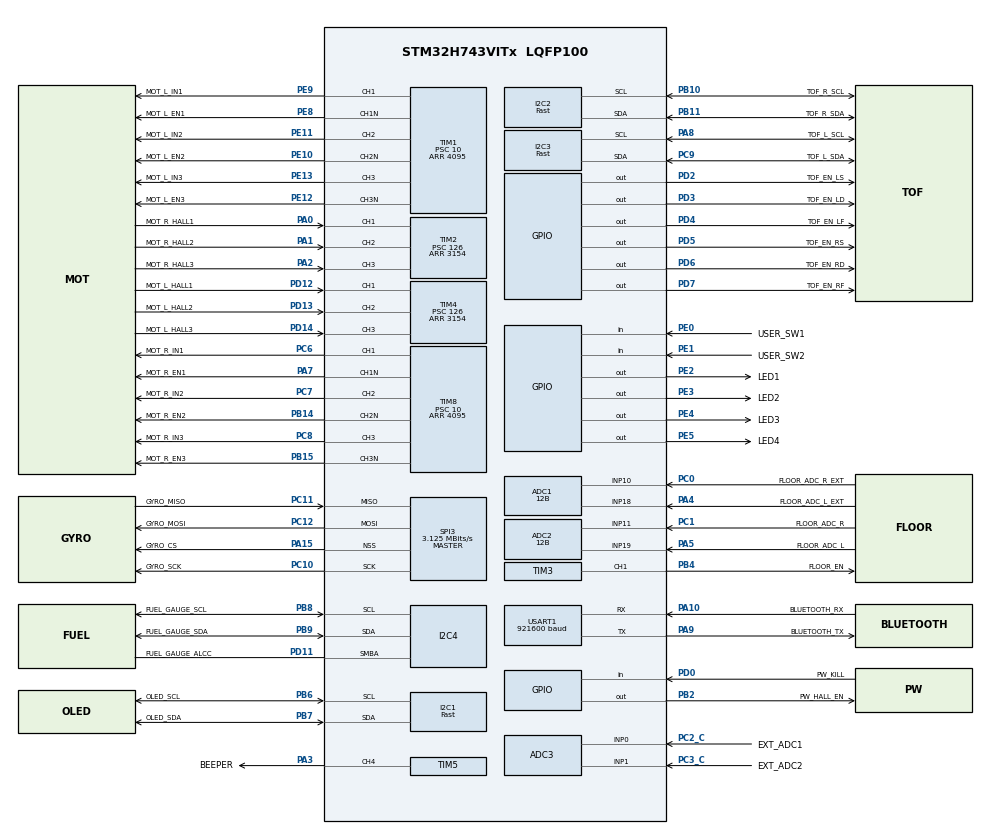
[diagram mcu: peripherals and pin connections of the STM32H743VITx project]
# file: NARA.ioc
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ADC1.BoostMode=ENABLE
ADC1.ClockPrescaler=ADC_CLOCK_ASYNC_DIV6
ADC1.ContinuousConvMode=DISABLE
ADC1.ConversionDataManagement=ADC_CONVERSIONDATA_DR
ADC1.DMAContinuousRequests=DISABLE
ADC1.DiscontinuousConvMode=DISABLE
ADC1.EOCSelection=ADC_EOC_SINGLE_CONV
ADC1.EnableAnalogWatchDog1=false
ADC1.EnableAnalogWatchDog2=false
ADC1.EnableAnalogWatchDog3=false
ADC1.EnableInjectedConversion=ENABLE
ADC1.EnableInjectedOversampling=DISABLE
ADC1.EnableRegularConversion=DISABLE
ADC1.ExternalTrigInjecConv=ADC_INJECTED_SOFTWARE_START
ADC1.ExternalTrigInjecConvEdge=ADC_EXTERNALTRIGINJECCONV_EDGE_NONE
ADC1.InjNumberOfConversion=2
ADC1.InjectedChannel-32\#ChannelInjectedConversion=ADC_CHANNEL_18
ADC1.InjectedChannel-33\#ChannelInjectedConversion=ADC_CHANNEL_10
ADC1.InjectedConvMode=None
ADC1.InjectedLeftBitShift=ADC_LEFTBITSHIFT_NONE
ADC1.InjectedOffsetNumber-32\#ChannelInjectedConversion=ADC_OFFSET_NONE
ADC1.InjectedOffsetNumber-33\#ChannelInjectedConversion=ADC_OFFSET_NONE
ADC1.InjectedQueue=DISABLE
ADC1.InjectedRank-32\#ChannelInjectedConversion=1
ADC1.InjectedRank-33\#ChannelInjectedConversion=2
ADC1.InjectedSamplingTime-32\#ChannelInjectedConversion=ADC_SAMPLETIME_2CYCLES_5
ADC1.InjectedSamplingTime-33\#ChannelInjectedConversion=ADC_SAMPLETIME_2CYCLES_5
ADC1.LowPowerAutoWait=DISABLE
ADC1.Overrun=ADC_OVR_DATA_PRESERVED
ADC1.Resolution=ADC_RESOLUTION_12B
ADC1.ScanConvMode=ADC_SCAN_ENABLE
ADC1.master=1
ADC2.EnableInjectedConversion=ENABLE
ADC2.EnableRegularConversion=DISABLE
ADC2.InjNumberOfConversion=2
ADC2.InjectedChannel-27\#ChannelInjectedConversion=ADC_CHANNEL_19
ADC2.InjectedChannel-28\#ChannelInjectedConversion=ADC_CHANNEL_11
ADC2.InjectedOffsetNumber-27\#ChannelInjectedConversion=ADC_OFFSET_NONE
ADC2.InjectedOffsetNumber-28\#ChannelInjectedConversion=ADC_OFFSET_NONE
ADC2.InjectedRank-27\#ChannelInjectedConversion=1
ADC2.InjectedRank-28\#ChannelInjectedConversion=2
ADC2.InjectedSamplingTime-27\#ChannelInjectedConversion=ADC_SAMPLETIME_2CYCLES_5
ADC2.InjectedSamplingTime-28\#ChannelInjectedConversion=ADC_SAMPLETIME_2CYCLES_5
ADC2.Resolution=ADC_RESOLUTION_12B
ADC3.Channel-0\#ChannelRegularConversion=ADC_CHANNEL_0
ADC3.NbrOfConversionFlag=1
ADC3.OffsetNumber-0\#ChannelRegularConversion=ADC_OFFSET_NONE
ADC3.Rank-0\#ChannelRegularConversion=1
ADC3.SamplingTime-0\#ChannelRegularConversion=ADC_SAMPLETIME_1CYCLE_5
CORTEX_M7.CPU_DCache=Enabled
CORTEX_M7.CPU_ICache=Enabled
Dma.Request0=USART1_TX
Dma.USART1_TX.0.Direction=DMA_MEMORY_TO_PERIPH
Dma.USART1_TX.0.EventEnable=DISABLE
Dma.USART1_TX.0.FIFOMode=DMA_FIFOMODE_DISABLE
Dma.USART1_TX.0.Instance=DMA2_Stream7
Dma.USART1_TX.0.MemDataAlignment=DMA_MDATAALIGN_BYTE
Dma.USART1_TX.0.MemInc=DMA_MINC_ENABLE
Dma.USART1_TX.0.Mode=DMA_NORMAL
Dma.USART1_TX.0.PeriphDataAlignment=DMA_PDATAALIGN_BYTE
Dma.USART1_TX.0.PeriphInc=DMA_PINC_DISABLE
Dma.USART1_TX.0.Polarity=HAL_DMAMUX_REQ_GEN_RISING
Dma.USART1_TX.0.Priority=DMA_PRIORITY_LOW
Dma.USART1_TX.0.RequestNumber=1
Dma.USART1_TX.0.SyncEnable=DISABLE
Dma.USART1_TX.0.SyncPolarity=HAL_DMAMUX_SYNC_NO_EVENT
Dma.USART1_TX.0.SyncRequestNumber=1
I2C1.Analog_Filter=I2C_ANALOGFILTER_DISABLE
I2C1.I2C_Speed_Mode=I2C_Fast
I2C1.Timing=0x009039BB
I2C2.Analog_Filter=I2C_ANALOGFILTER_DISABLE
I2C2.I2C_Speed_Mode=I2C_Fast
I2C2.Timing=0x009039BB
I2C3.Analog_Filter=I2C_ANALOGFILTER_DISABLE
I2C3.I2C_Speed_Mode=I2C_Fast
I2C3.Timing=0x009039BB
I2C4.SMBusAnalogFilter=SMBUS_ANALOGFILTER_DISABLE
I2C4.Timeout=0x000084C4
I2C4.Timing=0x10C0F1FF
Mcu.Family=STM32H7
Mcu.Name=STM32H743VITx
Mcu.Package=LQFP100
NVIC.ADC_IRQn=true\:0\:0\:false\:false\:true\:true
NVIC.DMA2_Stream7_IRQn=true\:0\:0\:false\:false\:true\:false
NVIC.PriorityGroup=NVIC_PRIORITYGROUP_1
NVIC.TIM1_BRK_IRQn=true\:1\:0\:true\:false\:true\:true
NVIC.TIM1_TRG_COM_IRQn=true\:0\:2\:false\:false\:true\:true
NVIC.TIM2_IRQn=true\:0\:1\:false\:false\:true\:true
NVIC.TIM4_IRQn=true\:0\:1\:false\:false\:true\:true
NVIC.TIM6_DAC_IRQn=true\:1\:0\:true\:false\:true\:true
NVIC.TIM7_IRQn=true\:0\:3\:false\:false\:true\:true
NVIC.TIM8_BRK_TIM12_IRQn=true\:1\:0\:true\:false\:true\:true
NVIC.TIM8_TRG_COM_TIM14_IRQn=true\:0\:2\:false\:false\:true\:true
NVIC.USART1_IRQn=true\:0\:1\:false\:false\:true\:true
PA0-WKUP.GPIO_Label=MOT_R_HALL1
PA0-WKUP.GPIO_PuPd=GPIO_PULLUP
PA0-WKUP.GPIO_Speed=GPIO_SPEED_FREQ_VERY_HIGH
PA0-WKUP.Signal=S_TIM2_CH1
PA1.GPIO_Label=MOT_R_HALL2
PA1.GPIO_PuPd=GPIO_PULLUP
PA1.GPIO_Speed=GPIO_SPEED_FREQ_VERY_HIGH
PA1.Signal=S_TIM2_CH2
PA10.GPIO_Label=BLUETOOTH_RX
PA10.GPIO_Speed=GPIO_SPEED_FREQ_VERY_HIGH
PA10.Mode=Asynchronous
PA10.Signal=USART1_RX
PA13.Mode=Serial_Wire
PA13.Signal=SYS_JTMS-SWDIO
PA14.Mode=Serial_Wire
PA14.Signal=SYS_JTCK-SWCLK
PA15.GPIO_Label=GYRO_CS
PA15.GPIO_Speed=GPIO_SPEED_FREQ_VERY_HIGH
PA15.Mode=NSS_Signal_Hard_Output
PA15.Signal=SPI3_NSS
PA2.GPIO_Label=MOT_R_HALL3
PA2.GPIO_PuPd=GPIO_PULLUP
PA2.GPIO_Speed=GPIO_SPEED_FREQ_VERY_HIGH
PA2.Signal=S_TIM2_CH3
PA3.GPIO_Label=BEEPER
PA3.GPIO_Speed=GPIO_SPEED_FREQ_VERY_HIGH
PA3.Signal=S_TIM5_CH4
PA4.GPIO_Label=FLOOR_ADC_L_EXT
PA4.Signal=ADCx_INP18
PA5.GPIO_Label=FLOOR_ADC_L
PA5.Signal=ADCx_INP19
PA7.GPIO_Label=MOT_R_EN1
PA7.GPIO_Speed=GPIO_SPEED_FREQ_VERY_HIGH
PA7.Mode=Output Compare1 CH1 CH1N
PA7.Signal=TIM8_CH1N
PA8.GPIO_Label=TOF_L_SCL
PA8.GPIO_PuPd=GPIO_PULLUP
PA8.GPIO_Speed=GPIO_SPEED_FREQ_VERY_HIGH
PA8.Mode=I2C
PA8.Signal=I2C3_SCL
PA9.GPIO_Label=BLUETOOTH_TX
PA9.GPIO_Speed=GPIO_SPEED_FREQ_VERY_HIGH
PA9.Mode=Asynchronous
PA9.Signal=USART1_TX
PB10.GPIO_Label=TOF_R_SCL
PB10.GPIO_PuPd=GPIO_PULLUP
PB10.GPIO_Speed=GPIO_SPEED_FREQ_VERY_HIGH
PB10.Mode=I2C
PB10.Signal=I2C2_SCL
PB11.GPIO_Label=TOF_R_SDA
PB11.GPIO_PuPd=GPIO_PULLUP
PB11.GPIO_Speed=GPIO_SPEED_FREQ_VERY_HIGH
PB11.Mode=I2C
PB11.Signal=I2C2_SDA
PB14.GPIO_Label=MOT_R_EN2
PB14.GPIO_Speed=GPIO_SPEED_FREQ_VERY_HIGH
PB14.Mode=Output Compare2 CH2 CH2N
PB14.Signal=TIM8_CH2N
PB15.GPIO_Label=MOT_R_EN3
PB15.GPIO_Speed=GPIO_SPEED_FREQ_VERY_HIGH
PB15.Mode=Output Compare3 CH3 CH3N
PB15.Signal=TIM8_CH3N
PB2.GPIO_Label=PW_HALL_EN
PB2.Signal=GPIO_Output
PB4.GPIO_Label=FLOOR_EN
PB4.Signal=S_TIM3_CH1
PB6.GPIO_Label=OLED_SCL
PB6.GPIO_Speed=GPIO_SPEED_FREQ_VERY_HIGH
PB6.Mode=I2C
PB6.Signal=I2C1_SCL
PB7.GPIO_Label=OLED_SDA
PB7.GPIO_Speed=GPIO_SPEED_FREQ_VERY_HIGH
PB7.Mode=I2C
PB7.Signal=I2C1_SDA
PB8.GPIO_Label=FUEL_GAUGE_SCL
PB8.GPIO_Speed=GPIO_SPEED_FREQ_VERY_HIGH
PB8.Mode=SMBus-Alert-mode
PB8.Signal=I2C4_SCL
PB9.GPIO_Label=FUEL_GAUGE_SDA
PB9.GPIO_Speed=GPIO_SPEED_FREQ_VERY_HIGH
PB9.Mode=SMBus-Alert-mode
PB9.Signal=I2C4_SDA
PC0.GPIO_Label=FLOOR_ADC_R_EXT
PC0.Signal=ADCx_INP10
PC1.GPIO_Label=FLOOR_ADC_R
PC1.Signal=ADCx_INP11
PC10.GPIO_Label=GYRO_SCK
PC10.GPIO_Speed=GPIO_SPEED_FREQ_VERY_HIGH
PC10.Mode=Full_Duplex_Master
PC10.Signal=SPI3_SCK
PC11.GPIO_Label=GYRO_MISO
PC11.GPIO_Speed=GPIO_SPEED_FREQ_VERY_HIGH
PC11.Mode=Full_Duplex_Master
PC11.Signal=SPI3_MISO
PC12.GPIO_Label=GYRO_MOSI
PC12.GPIO_Speed=GPIO_SPEED_FREQ_VERY_HIGH
PC12.Mode=Full_Duplex_Master
PC12.Signal=SPI3_MOSI
PC13.GPIO_Label=WKUP
PC13.Mode=SYS_WakeUp2
PC13.Signal=SYS_WKUP2
PC2_C.GPIO_Label=EXT_ADC1
PC2_C.Mode=IN0-Single-Ended
PC2_C.Signal=ADC3_INP0
PC3_C.GPIO_Label=EXT_ADC2
PC3_C.Mode=IN1-Single-Ended
PC3_C.Signal=ADC3_INP1
PC6.GPIO_Label=MOT_R_IN1
PC6.GPIO_Speed=GPIO_SPEED_FREQ_VERY_HIGH
PC6.Signal=S_TIM8_CH1
PC7.GPIO_Label=MOT_R_IN2
PC7.GPIO_Speed=GPIO_SPEED_FREQ_VERY_HIGH
PC7.Signal=S_TIM8_CH2
PC8.GPIO_Label=MOT_R_IN3
PC8.GPIO_Speed=GPIO_SPEED_FREQ_VERY_HIGH
PC8.Signal=S_TIM8_CH3
PC9.GPIO_Label=TOF_L_SDA
PC9.GPIO_PuPd=GPIO_PULLUP
PC9.GPIO_Speed=GPIO_SPEED_FREQ_VERY_HIGH
PC9.Mode=I2C
PC9.Signal=I2C3_SDA
PD0.GPIO_Label=PW_KILL
PD0.Signal=GPIO_Input
PD11.GPIO_Label=FUEL_GAUGE_ALCC
PD11.GPIO_Speed=GPIO_SPEED_FREQ_VERY_HIGH
PD11.Mode=SMBus-Alert-mode
PD11.Signal=I2C4_SMBA
PD12.GPIO_Label=MOT_L_HALL1
PD12.GPIO_PuPd=GPIO_PULLUP
PD12.GPIO_Speed=GPIO_SPEED_FREQ_VERY_HIGH
PD12.Signal=S_TIM4_CH1
PD13.GPIO_Label=MOT_L_HALL2
PD13.GPIO_PuPd=GPIO_PULLUP
PD13.GPIO_Speed=GPIO_SPEED_FREQ_VERY_HIGH
PD13.Signal=S_TIM4_CH2
PD14.GPIO_Label=MOT_L_HALL3
PD14.GPIO_PuPd=GPIO_PULLUP
PD14.GPIO_Speed=GPIO_SPEED_FREQ_VERY_HIGH
PD14.Signal=S_TIM4_CH3
PD2.GPIO_Label=TOF_EN_LS
PD2.GPIO_Speed=GPIO_SPEED_FREQ_MEDIUM
PD2.PinState=GPIO_PIN_RESET
PD2.Signal=GPIO_Output
PD3.GPIO_Label=TOF_EN_LD
PD3.GPIO_Speed=GPIO_SPEED_FREQ_MEDIUM
PD3.PinState=GPIO_PIN_RESET
PD3.Signal=GPIO_Output
PD4.GPIO_Label=TOF_EN_LF
PD4.GPIO_Speed=GPIO_SPEED_FREQ_MEDIUM
PD4.PinState=GPIO_PIN_RESET
PD4.Signal=GPIO_Output
PD5.GPIO_Label=TOF_EN_RS
PD5.GPIO_Speed=GPIO_SPEED_FREQ_MEDIUM
PD5.PinState=GPIO_PIN_RESET
PD5.Signal=GPIO_Output
PD6.GPIO_Label=TOF_EN_RD
PD6.GPIO_Speed=GPIO_SPEED_FREQ_MEDIUM
PD6.PinState=GPIO_PIN_RESET
PD6.Signal=GPIO_Output
PD7.GPIO_Label=TOF_EN_RF
PD7.GPIO_Speed=GPIO_SPEED_FREQ_MEDIUM
PD7.PinState=GPIO_PIN_RESET
PD7.Signal=GPIO_Output
PE0.GPIO_Label=USER_SW1
PE0.Signal=GPIO_Input
PE1.GPIO_Label=USER_SW2
PE1.Signal=GPIO_Input
PE10.GPIO_Label=MOT_L_EN2
PE10.GPIO_Speed=GPIO_SPEED_FREQ_VERY_HIGH
PE10.Mode=Output Compare2 CH2 CH2N
PE10.Signal=TIM1_CH2N
PE11.GPIO_Label=MOT_L_IN2
PE11.GPIO_Speed=GPIO_SPEED_FREQ_VERY_HIGH
PE11.Signal=S_TIM1_CH2
PE12.GPIO_Label=MOT_L_EN3
PE12.GPIO_Speed=GPIO_SPEED_FREQ_VERY_HIGH
PE12.Mode=Output Compare3 CH3 CH3N
PE12.Signal=TIM1_CH3N
PE13.GPIO_Label=MOT_L_IN3
PE13.GPIO_Speed=GPIO_SPEED_FREQ_VERY_HIGH
PE13.Signal=S_TIM1_CH3
PE2.GPIO_Label=LED1
PE2.GPIO_Speed=GPIO_SPEED_FREQ_VERY_HIGH
PE2.Signal=GPIO_Output
PE3.GPIO_Label=LED2
PE3.GPIO_Speed=GPIO_SPEED_FREQ_VERY_HIGH
PE3.Signal=GPIO_Output
PE4.GPIO_Label=LED3
PE4.GPIO_Speed=GPIO_SPEED_FREQ_VERY_HIGH
PE4.Signal=GPIO_Output
PE5.GPIO_Label=LED4
PE5.GPIO_Speed=GPIO_SPEED_FREQ_VERY_HIGH
PE5.Signal=GPIO_Output
PE8.GPIO_Label=MOT_L_EN1
PE8.GPIO_Speed=GPIO_SPEED_FREQ_VERY_HIGH
PE8.Mode=Output Compare1 CH1 CH1N
PE8.Signal=TIM1_CH1N
PE9.GPIO_Label=MOT_L_IN1
PE9.GPIO_Speed=GPIO_SPEED_FREQ_VERY_HIGH
PE9.Signal=S_TIM1_CH1
ProjectManager.HeapSize=0x200
ProjectManager.StackSize=0x400
ProjectManager.TargetToolchain=SW4STM32
RCC.ADCFreq_Value=160000000
RCC.APB1Freq_Value=100000000
RCC.APB2Freq_Value=100000000
RCC.APB3Freq_Value=100000000
RCC.APB4Freq_Value=100000000
RCC.CortexFreq_Value=400000000
RCC.D1PPRE=RCC_APB3_DIV2
RCC.D2PPRE1=RCC_APB1_DIV2
RCC.D2PPRE2=RCC_APB2_DIV2
RCC.D3PPRE=RCC_APB4_DIV2
RCC.DIVM1=4
RCC.DIVM2=4
RCC.DIVN1=50
RCC.DIVN2=10
RCC.DIVP2=1
RCC.FLatency=FLASH_LATENCY_4
RCC.HCLKFreq_Value=200000000
RCC.HPRE=RCC_HCLK_DIV2
RCC.SYSCLKFreq_VALUE=400000000
RCC.SYSCLKSource=RCC_SYSCLKSOURCE_PLLCLK
RCC.USBFreq_Value=400000000
SH.ADCx_INP10.0=ADC1_INP10,IN10-Single-Ended
SH.ADCx_INP11.0=ADC2_INP11,IN11-Single-Ended
SH.ADCx_INP18.0=ADC1_INP18,IN18-Single-Ended
SH.ADCx_INP19.0=ADC2_INP19,IN19-Single-Ended
SH.S_TIM1_CH1.0=TIM1_CH1,Output Compare1 CH1 CH1N
SH.S_TIM1_CH2.0=TIM1_CH2,Output Compare2 CH2 CH2N
SH.S_TIM1_CH3.0=TIM1_CH3,Output Compare3 CH3 CH3N
SH.S_TIM2_CH1.0=TIM2_CH1,Xored_Inputs_Hall_Sensor_Interface
SH.S_TIM2_CH2.0=TIM2_CH2,Xored_Inputs_Hall_Sensor_Interface
SH.S_TIM2_CH3.0=TIM2_CH3,Xored_Inputs_Hall_Sensor_Interface
SH.S_TIM3_CH1.0=TIM3_CH1,PWM Generation1 CH1
SH.S_TIM4_CH1.0=TIM4_CH1,Xored_Inputs_Hall_Sensor_Interface
SH.S_TIM4_CH2.0=TIM4_CH2,Xored_Inputs_Hall_Sensor_Interface
SH.S_TIM4_CH3.0=TIM4_CH3,Xored_Inputs_Hall_Sensor_Interface
SH.S_TIM5_CH4.0=TIM5_CH4,PWM Generation4 CH4
SH.S_TIM8_CH1.0=TIM8_CH1,Output Compare1 CH1 CH1N
SH.S_TIM8_CH2.0=TIM8_CH2,Output Compare2 CH2 CH2N
SH.S_TIM8_CH3.0=TIM8_CH3,Output Compare3 CH3 CH3N
SPI3.BaudRatePrescaler=SPI_BAUDRATEPRESCALER_128
SPI3.CalculateBaudRate=3.125 MBits/s
SPI3.Direction=SPI_DIRECTION_2LINES
SPI3.Mode=SPI_MODE_MASTER
SPI3.VirtualNSS=VM_NSSHARD
SPI3.VirtualType=VM_MASTER
TIM1.AutomaticOutput=TIM_AUTOMATICOUTPUT_ENABLE
TIM1.Break2State=TIM_BREAK2_DISABLE
TIM1.Channel-Output\ Compare1\ CH1\ CH1N=TIM_CHANNEL_1
TIM1.Channel-Output\ Compare2\ CH2\ CH2N=TIM_CHANNEL_2
TIM1.Channel-Output\ Compare3\ CH3\ CH3N=TIM_CHANNEL_3
TIM1.DeadTime=18
TIM1.OCIdleState_1=TIM_OCIDLESTATE_SET
TIM1.OCIdleState_2=TIM_OCIDLESTATE_SET
TIM1.OCIdleState_3=TIM_OCIDLESTATE_SET
TIM1.OCNIdleState_1=TIM_OCNIDLESTATE_SET
TIM1.OCNIdleState_2=TIM_OCNIDLESTATE_SET
TIM1.OCNIdleState_3=TIM_OCNIDLESTATE_SET
TIM1.OffStateIDLEMode=TIM_OSSI_ENABLE
TIM1.OffStateRunMode=TIM_OSSR_ENABLE
TIM1.Period=4095
TIM1.Prescaler=10
TIM1.Pulse-Output\ Compare1\ CH1\ CH1N=2047
TIM1.Pulse-Output\ Compare2\ CH2\ CH2N=1023
TIM1.Pulse-Output\ Compare3\ CH3\ CH3N=511
TIM2.Commutation_Delay=1
TIM2.IC1Filter=0xF
TIM2.Period=3154
TIM2.Prescaler=126
TIM3.Channel-PWM\ Generation1\ CH1=TIM_CHANNEL_1
TIM3.Period=1000
TIM3.Prescaler=1000
TIM4.Commutation_Delay=1
TIM4.IC1Filter=0xF
TIM4.Period=3154
TIM4.Prescaler=126
TIM5.Channel-PWM\ Generation4\ CH4=TIM_CHANNEL_4
TIM5.OCPolarity_4=TIM_OCPOLARITY_LOW
TIM5.Period=100
TIM5.Prescaler=10000
TIM5.Pulse-PWM\ Generation4\ CH4=50
TIM6.Period=10
TIM6.Prescaler=60000
TIM7.Period=10
TIM7.Prescaler=60000
TIM8.AutomaticOutput=TIM_AUTOMATICOUTPUT_ENABLE
TIM8.Channel-Output\ Compare1\ CH1\ CH1N=TIM_CHANNEL_1
TIM8.Channel-Output\ Compare2\ CH2\ CH2N=TIM_CHANNEL_2
TIM8.Channel-Output\ Compare3\ CH3\ CH3N=TIM_CHANNEL_3
TIM8.DeadTime=18
TIM8.OCIdleState_1=TIM_OCIDLESTATE_SET
TIM8.OCIdleState_2=TIM_OCIDLESTATE_SET
TIM8.OCIdleState_3=TIM_OCIDLESTATE_SET
TIM8.OCNIdleState_1=TIM_OCNIDLESTATE_SET
TIM8.OCNIdleState_2=TIM_OCNIDLESTATE_SET
TIM8.OCNIdleState_3=TIM_OCNIDLESTATE_SET
TIM8.OffStateIDLEMode=TIM_OSSI_ENABLE
TIM8.OffStateRunMode=TIM_OSSR_ENABLE
TIM8.Period=4095
TIM8.Prescaler=10
TIM8.Pulse-Output\ Compare1\ CH1\ CH1N=2047
TIM8.Pulse-Output\ Compare2\ CH2\ CH2N=1023
TIM8.Pulse-Output\ Compare3\ CH3\ CH3N=511
USART1.BaudRate=921600
USART1.VirtualMode-Asynchronous=VM_ASYNC
USART1.WordLength=WORDLENGTH_8B
VP_TIM1_VS_ClockSourceITR.Mode=TriggerSource_ITR3
VP_TIM1_VS_ControllerModeTrigger.Mode=Trigger Mode
VP_TIM2_VS_ClockSourceINT.Mode=Internal
VP_TIM3_VS_ClockSourceINT.Mode=Internal
VP_TIM4_VS_ClockSourceINT.Mode=Internal
VP_TIM6_VS_ClockSourceINT.Mode=Enable_Timer
VP_TIM7_VS_ClockSourceINT.Mode=Enable_Timer
VP_TIM8_VS_ClockSourceITR.Mode=TriggerSource_ITR1
VP_TIM8_VS_ControllerModeTrigger.Mode=Trigger Mode
board=NARA

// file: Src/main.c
/**
  ******************************************************************************
  * @file           : main.c
  * @brief          : Main program body
  ******************************************************************************
  ** This notice applies to any and all portions of this file
  * that are not between comment pairs USER CODE BEGIN and
  * USER CODE END. Other portions of this file, whether
  * inserted by the user or by software development tools
  * are owned by their respective copyright owners.
  *
  * COPYRIGHT(c) 2018 STMicroelectronics
  *
  * Redistribution and use in source and binary forms, with or without modification,
  * are permitted provided that the following conditions are met:
  *   1. Redistributions of source code must retain the above copyright notice,
  *      this list of conditions and the following disclaimer.
  *   2. Redistributions in binary form must reproduce the above copyright notice,
  *      this list of conditions and the following disclaimer in the documentation
  *      and/or other materials provided with the distribution.
  *   3. Neither the name of STMicroelectronics nor the names of its contributors
  *      may be used to endorse or promote products derived from this software
  *      without specific prior written permission.
  *
  * THIS SOFTWARE IS PROVIDED BY THE COPYRIGHT HOLDERS AND CONTRIBUTORS "AS IS"
  * AND ANY EXPRESS OR IMPLIED WARRANTIES, INCLUDING, BUT NOT LIMITED TO, THE
  * IMPLIED WARRANTIES OF MERCHANTABILITY AND FITNESS FOR A PARTICULAR PURPOSE ARE
  * DISCLAIMED. IN NO EVENT SHALL THE COPYRIGHT HOLDER OR CONTRIBUTORS BE LIABLE
  * FOR ANY DIRECT, INDIRECT, INCIDENTAL, SPECIAL, EXEMPLARY, OR CONSEQUENTIAL
  * DAMAGES (INCLUDING, BUT NOT LIMITED TO, PROCUREMENT OF SUBSTITUTE GOODS OR
  * SERVICES; LOSS OF USE, DATA, OR PROFITS; OR BUSINESS INTERRUPTION) HOWEVER
  * CAUSED AND ON ANY THEORY OF LIABILITY, WHETHER IN CONTRACT, STRICT LIABILITY,
  * OR TORT (INCLUDING NEGLIGENCE OR OTHERWISE) ARISING IN ANY WAY OUT OF THE USE
  * OF THIS SOFTWARE, EVEN IF ADVISED OF THE POSSIBILITY OF SUCH DAMAGE.
  *
  ******************************************************************************
  */
#include "main.h"
#include "stm32h7xx_hal.h"
#include "adc.h"
#include "dma.h"
#include "i2c.h"
#include "spi.h"
#include "tim.h"
#include "usart.h"
#include "gpio.h"

/* USER CODE BEGIN Includes */

#include "application/mainApp/mainApp.h"
#include "peripherals/telemeters/telemeters.h"
#include "peripherals/tone/tone.h"
#include "peripherals/motors/bldc.h"
#include "peripherals/times_base/times_base.h"
#include "peripherals/encoders/encoder.h"
#include "peripherals/floorSensors/floorSensors.h"

/* USER CODE END Includes */

/* USER CODE BEGIN PV */
/* Private variables ---------------------------------------------------------*/

/* USER CODE END PV */

void SystemClock_Config(void);

/* USER CODE BEGIN PFP */
/* Private function prototypes -----------------------------------------------*/

/* USER CODE END PFP */

int main(void)
{

  /* Enable I-Cache-------------------------------------------------------------*/
  SCB_EnableICache();

  /* Enable D-Cache-------------------------------------------------------------*/
  SCB_EnableDCache();

  /* MCU Configuration----------------------------------------------------------*/

  /* Reset of all peripherals, Initializes the Flash interface and the Systick. */
  HAL_Init();

  /* Configure the system clock */
  SystemClock_Config();

  /* Initialize all configured peripherals */
  MX_GPIO_Init();
  MX_DMA_Init();
  MX_ADC3_Init();
  MX_I2C1_Init();
  MX_I2C2_Init();
  MX_I2C3_Init();
  MX_I2C4_SMBUS_Init();
  MX_SPI3_Init();
  MX_TIM1_Init();
  MX_TIM2_Init();
  MX_TIM4_Init();
  MX_TIM5_Init();
  MX_TIM8_Init();
  MX_USART1_UART_Init();
  MX_TIM6_Init();
  MX_TIM7_Init();
  MX_ADC1_Init();
  MX_ADC2_Init();
  MX_TIM3_Init();
  /* USER CODE BEGIN 2 */

	timesBaseInit();
	toneInit();
	printf("HELLO NARA WORLD \n\r");
	ledPowerBlink(480, 20);
	welcomeTone(100);

	mainApp();

  /* USER CODE END 2 */

  /* Infinite loop */
	while (1)
	{

	}

}

void SystemClock_Config(void)
{

  RCC_OscInitTypeDef RCC_OscInitStruct;
  RCC_ClkInitTypeDef RCC_ClkInitStruct;
  RCC_PeriphCLKInitTypeDef PeriphClkInitStruct;

    /**Supply configuration update enable
    */
  MODIFY_REG(PWR->CR3, PWR_CR3_SCUEN, 0);

    /**Configure the main internal regulator output voltage
    */
  __HAL_PWR_VOLTAGESCALING_CONFIG(PWR_REGULATOR_VOLTAGE_SCALE1);

  while ((PWR->D3CR & (PWR_D3CR_VOSRDY)) != PWR_D3CR_VOSRDY)
  {

  }
    /**Macro to configure the PLL clock source
    */
  __HAL_RCC_PLL_PLLSOURCE_CONFIG(RCC_PLLSOURCE_HSI);

    /**Initializes the CPU, AHB and APB busses clocks
    */
  RCC_OscInitStruct.OscillatorType = RCC_OSCILLATORTYPE_HSI;
  RCC_OscInitStruct.HSIState = RCC_HSI_DIV1;
  RCC_OscInitStruct.HSICalibrationValue = 16;
  RCC_OscInitStruct.PLL.PLLState = RCC_PLL_ON;
  RCC_OscInitStruct.PLL.PLLSource = RCC_PLLSOURCE_HSI;
  RCC_OscInitStruct.PLL.PLLM = 4;
  RCC_OscInitStruct.PLL.PLLN = 50;
  RCC_OscInitStruct.PLL.PLLP = 2;
  RCC_OscInitStruct.PLL.PLLQ = 2;
  RCC_OscInitStruct.PLL.PLLR = 2;
  RCC_OscInitStruct.PLL.PLLRGE = RCC_PLL1VCIRANGE_3;
  RCC_OscInitStruct.PLL.PLLVCOSEL = RCC_PLL1VCOWIDE;
  RCC_OscInitStruct.PLL.PLLFRACN = 0;
  if (HAL_RCC_OscConfig(&RCC_OscInitStruct) != HAL_OK)
  {
    _Error_Handler(__FILE__, __LINE__);
  }

    /**Initializes the CPU, AHB and APB busses clocks
    */
  RCC_ClkInitStruct.ClockType = RCC_CLOCKTYPE_HCLK|RCC_CLOCKTYPE_SYSCLK
                              |RCC_CLOCKTYPE_PCLK1|RCC_CLOCKTYPE_PCLK2
                              |RCC_CLOCKTYPE_D3PCLK1|RCC_CLOCKTYPE_D1PCLK1;
  RCC_ClkInitStruct.SYSCLKSource = RCC_SYSCLKSOURCE_PLLCLK;
  RCC_ClkInitStruct.SYSCLKDivider = RCC_SYSCLK_DIV1;
  RCC_ClkInitStruct.AHBCLKDivider = RCC_HCLK_DIV2;
  RCC_ClkInitStruct.APB3CLKDivider = RCC_APB3_DIV2;
  RCC_ClkInitStruct.APB1CLKDivider = RCC_APB1_DIV2;
  RCC_ClkInitStruct.APB2CLKDivider = RCC_APB2_DIV2;
  RCC_ClkInitStruct.APB4CLKDivider = RCC_APB4_DIV2;

  if (HAL_RCC_ClockConfig(&RCC_ClkInitStruct, FLASH_LATENCY_4) != HAL_OK)
  {
    _Error_Handler(__FILE__, __LINE__);
  }

  PeriphClkInitStruct.PeriphClockSelection = RCC_PERIPHCLK_USART1|RCC_PERIPHCLK_SPI3
                              |RCC_PERIPHCLK_I2C2|RCC_PERIPHCLK_I2C3
                              |RCC_PERIPHCLK_ADC|RCC_PERIPHCLK_I2C1
                              |RCC_PERIPHCLK_I2C4;
  PeriphClkInitStruct.PLL2.PLL2M = 4;
  PeriphClkInitStruct.PLL2.PLL2N = 10;
  PeriphClkInitStruct.PLL2.PLL2P = 1;
  PeriphClkInitStruct.PLL2.PLL2Q = 2;
  PeriphClkInitStruct.PLL2.PLL2R = 2;
  PeriphClkInitStruct.PLL2.PLL2RGE = RCC_PLL2VCIRANGE_3;
  PeriphClkInitStruct.PLL2.PLL2VCOSEL = RCC_PLL2VCOMEDIUM;
  PeriphClkInitStruct.PLL2.PLL2FRACN = 0;
  PeriphClkInitStruct.Spi123ClockSelection = RCC_SPI123CLKSOURCE_PLL;
  PeriphClkInitStruct.Usart16ClockSelection = RCC_USART16CLKSOURCE_D2PCLK2;
  PeriphClkInitStruct.I2c123ClockSelection = RCC_I2C123CLKSOURCE_D2PCLK1;
  PeriphClkInitStruct.I2c4ClockSelection = RCC_I2C4CLKSOURCE_D3PCLK1;
  PeriphClkInitStruct.AdcClockSelection = RCC_ADCCLKSOURCE_PLL2;
  if (HAL_RCCEx_PeriphCLKConfig(&PeriphClkInitStruct) != HAL_OK)
  {
    _Error_Handler(__FILE__, __LINE__);
  }

    /**Configure the Systick interrupt time
    */
  HAL_SYSTICK_Config(SystemCoreClock/1000);

    /**Configure the Systick
    */
  HAL_SYSTICK_CLKSourceConfig(SYSTICK_CLKSOURCE_HCLK);

  /* SysTick_IRQn interrupt configuration */
  HAL_NVIC_SetPriority(SysTick_IRQn, 0, 0);
}

void _Error_Handler(char *file, int line)
{
  /* USER CODE BEGIN Error_Handler_Debug */
	/* User can add his own implementation to report the HAL error return state */
	printf("error in file %s at line %d\n", file, line);
	while(1)
	{
	}
  /* USER CODE END Error_Handler_Debug */
}

/************************ (C) COPYRIGHT STMicroelectronics *****END OF FILE****/
